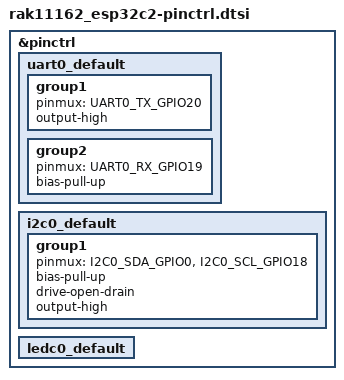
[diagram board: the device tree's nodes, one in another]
/*
 * Copyright (c) 2026 RAKwireless Technology Limited
 * SPDX-License-Identifier: Apache-2.0
 */

#include <zephyr/dt-bindings/pinctrl/esp32c2-pinctrl.h>

&pinctrl {
	uart0_default: uart0_default {
		group1 {
			pinmux = <UART0_TX_GPIO20>;
			output-high;
		};

		group2 {
			pinmux = <UART0_RX_GPIO19>;
			bias-pull-up;
		};
	};

	i2c0_default: i2c0_default {
		group1 {
			pinmux = <I2C0_SDA_GPIO0>,
				 <I2C0_SCL_GPIO18>;
			bias-pull-up;
			drive-open-drain;
			output-high;
		};
	};

	ledc0_default: ledc0_default {
	};
};
